# CY8C5888LTI_LP097 register map
File version: 0.1
Registers are 8-bit, read-write, no defined reset value unless marked. A register's access mark holds for its fields unless they carry their own. Offsets are from the block's base; [hi:lo] are bit positions; {n}, {i} and the like mark numbered series; 'fields as' and 'values as' point back to an identical list.

## Timer_RPM
Base 0x00000000
0x4000640C Timer_RPM_COUNTER 16-bit — UDB.A0 - Current Down Counter Value
0x4000642C Timer_RPM_PERIOD 16-bit — UDB.D0 - Assigned Period
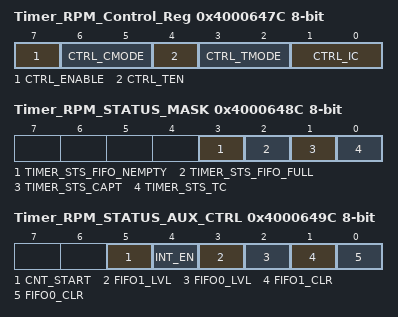
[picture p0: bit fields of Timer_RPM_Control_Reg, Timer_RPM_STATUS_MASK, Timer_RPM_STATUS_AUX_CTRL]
0x4000647C Timer_RPM_Control_Reg — UDB Control Register - Assigned Control Register Value
  [7] CTRL_ENABLE — Enable the Timer
  [6:5] CTRL_CMODE — Capture Mode
  [4] CTRL_TEN — Trigger Enable Bit
  [3:2] CTRL_TMODE — Trigger Mode
  [1:0] CTRL_IC — Interrupt Count
0x4000648C Timer_RPM_STATUS_MASK — UDB Status bits Interrupt Mask Enable Register
  [3] TIMER_STS_FIFO_NEMPTY ro — FIFO Empty status
  [2] TIMER_STS_FIFO_FULL ro — FIFO Full Status
  [1] TIMER_STS_CAPT ro — Enables the Interrupt on Capture
  [0] TIMER_STS_TC ro — Enables the Interrupt on TC
0x4000649C Timer_RPM_STATUS_AUX_CTRL — UDB Auxilliary Control Register
  [5] CNT_START — FIFO0 clear
    0=E_CNT_START0 (Disable counter); 1=E_CNT_START1 (Enable counter)
  [4] INT_EN
    0=E_INT_EN0 (Interrupt disabled); 1=E_INT_EN1 (Interrupt enabled)
  [3] FIFO1_LVL — FIFO level
    0=E_FIFO_LVL_0 (FIFO LVL: input mode: FIFO not full; output mode: FIFO not empty); 1=E_FIFO_LVL_1 (FIFO LVL: input mode: FIFO at least 1/2 empty; output mode: FIFO at least 1/2 full)
  [2] FIFO0_LVL — FIFO level
    values as FIFO1_LVL
  [1] FIFO1_CLR — FIFO1 clear
    0=E_FIFO_CLR_0 (Normal FIFO operation); 1=E_FIFO_CLR_1 (Clear FIFO state)
  [0] FIFO0_CLR — FIFO0 clear
    values as FIFO1_CLR

## PWM_motor
Base 0x00000000
0x4000642A PWM_motor_COMPARE_Reg_ — UDB.D0 - Assigned Compare Value
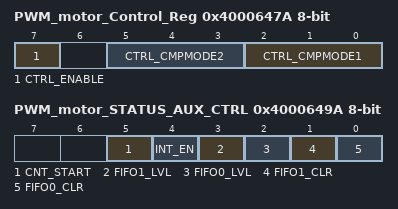
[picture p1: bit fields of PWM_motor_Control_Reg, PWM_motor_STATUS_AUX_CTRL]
0x4000647A PWM_motor_Control_Reg — UDB Control Register - Assigned Control Register Value
  [7] CTRL_ENABLE — Enable the PWM
  [5:3] CTRL_CMPMODE2 — Compare mode 2
  [2:0] CTRL_CMPMODE1 — Compare mode 1
0x4000649A PWM_motor_STATUS_AUX_CTRL — UDB Auxilliary Control Register
  [5] CNT_START — FIFO0 clear
    0=E_CNT_START0 (Disable counter); 1=E_CNT_START1 (Enable counter)
  [4] INT_EN
    0=E_INT_EN0 (Interrupt disabled); 1=E_INT_EN1 (Interrupt enabled)
  [3] FIFO1_LVL — FIFO level
    0=E_FIFO_LVL_0 (FIFO LVL: input mode: FIFO not full; output mode: FIFO not empty); 1=E_FIFO_LVL_1 (FIFO LVL: input mode: FIFO at least 1/2 empty; output mode: FIFO at least 1/2 full)
  [2] FIFO0_LVL — FIFO level
    values as FIFO1_LVL
  [1] FIFO1_CLR — FIFO1 clear
    0=E_FIFO_CLR_0 (Normal FIFO operation); 1=E_FIFO_CLR_1 (Clear FIFO state)
  [0] FIFO0_CLR — FIFO0 clear
    values as FIFO1_CLR

## Control_Reg_motor_reset
Base 0x4000647B
0x00 Control_Reg_motor_reset_CONTROL_REG

## CAN_1
Base 0x00000000
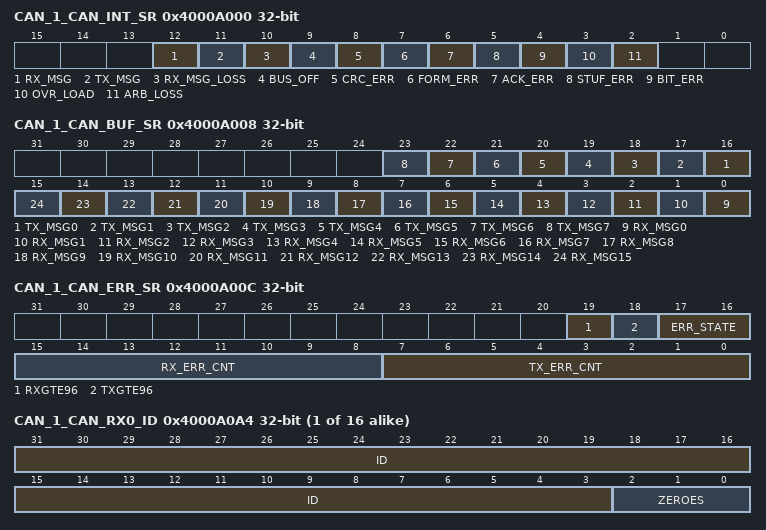
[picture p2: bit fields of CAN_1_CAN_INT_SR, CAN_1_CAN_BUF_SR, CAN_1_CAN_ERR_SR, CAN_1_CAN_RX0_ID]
0x4000A000 CAN_1_CAN_INT_SR 32-bit — The interrupt status register stores internal interrupt events. ? Once a bit is set it remains set until it is cleared by writing a '1' to it. ? The interrupt enable register has no effect on the interrupt status register. ? A pending interrupt occurs when the flag is set to '1'. To acknowledge an interrupt, set the flag to '1'
  [12] RX_MSG — Msg Recieved
  [11] TX_MSG — Tx msg Sent
  [10] RX_MSG_LOSS — Rx msg loss Interrupt
  [9] BUS_OFF — Bus Off State
  [8] CRC_ERR — CRC Error Interrupt
  [7] FORM_ERR — Form Error Interrupt
  [6] ACK_ERR — Ack Error Interrupt
  [5] STUF_ERR — Stuff Error Interrupt
  [4] BIT_ERR — Bit Error Interrupt
  [3] OVR_LOAD — Overload Interrupt
  [2] ARB_LOSS — Arbitration Loss
0x4000A008 CAN_1_CAN_BUF_SR 32-bit — These status indicators bundle the respective flags from all RxMessage and TxMessage buffers. ? Note All flags are read only. To acknowledge a MsgAv flag, the CPU must write to the respective RxMessage buffer
  [n+16] TX_MSG{n} (n=0..7) — Tx req Pending for Tx Msg{n}
  [n] RX_MSG{n} (n=0..15) — Rx Msg{n} Available
0x4000A00C CAN_1_CAN_ERR_SR 32-bit — Status indicators are provided to report the CAN controller error state, receive error count, and transmit error count. ? Special flags report error counter values equal to or in excess of 96 errors are available to indicate heavily disturbed bus situations. ? The transmitter error counter according to the CAN standard. When it is greater than 255 Decimal, it is fixed at 255 Decimal.
  [19] RXGTE96 — Rx Error Count is greater or equal to 96 Decimal
  [18] TXGTE96 — Tx Error Count is greater or equal to 96 Decimal
  [17:16] ERR_STATE — Error State of CAN node, 00 error active, 01 error passive, 1x bus off
  [15:8] RX_ERR_CNT — Rx error Count. When in bus-off state,this counter is used to count 128 groups of 11 recessive bits
  [7:0] TX_ERR_CNT — Tx error Count
{0x4000A024+0x10*i} CAN_1_CAN_TX{i}_ID 32-bit (i=0..7) — CAN Tx Msg Identifier
  [31:3] ID — Tx Msg Indentifier
{0x4000A028+0x10*i} CAN_1_CAN_TX{i}_DH 32-bit (i=0..7) — CAN Tx Msg Upper Data Bytes
  [31:0] DATA_HIGH — Upper Data Bytes
{0x4000A02C+0x10*i} CAN_1_CAN_TX{i}_DL 32-bit (i=0..7) — CAN Tx Msg Lower Data Bytes
  [31:0] DATA_LOW — Lower Data Bytes
{0x4000A0A4+0x20*i} CAN_1_CAN_RX{i}_ID 32-bit (i=0..15) — The register contains Rx Msg Identifier
  [31:3] ID — Rx Msg Indentifier
  [2:0] ZEROES — zeros
{0x4000A0A8+0x20*i} CAN_1_CAN_RX{i}_DH 32-bit (i=0..15) — The register contains the Rx Msg Upper Data Bytes
  [31:0] DATA_HIGH — Upper Data Bytes
{0x4000A0AC+0x20*i} CAN_1_CAN_RX{i}_DL 32-bit (i=0..15) — The register contains the Rx Msg Lover Data Bytes
  [31:0] DATA_LOW — Lower Data Bytes

## VDAC8_1
Base 0x00000000
0x400043A8 VDAC8_PM_ACT_CFG — Active Power Mode Configuration Register 8
  [4:0] en_dac — Enable DAC block(s). Populated subsystems are counted from the LSB
0x400043B8 VDAC8_PM_STBY_CFG — Standby Power Mode Configuration Register 8
  fields as VDAC8_PM_ACT_CFG
0x4000460A VDAC8_TR
  [7:0] tr — 8 Calibration bits
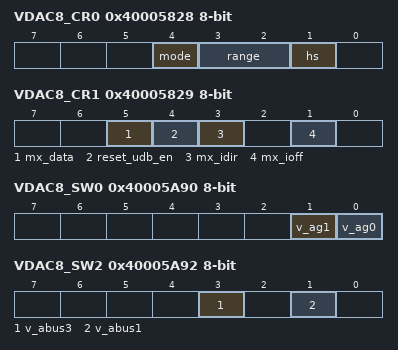
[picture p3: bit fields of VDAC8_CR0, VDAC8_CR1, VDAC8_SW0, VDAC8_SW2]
0x40005828 VDAC8_CR0 — DAC Block Control Register 0
  [4] mode ro — Mode Bit
    0=DAC_MODE_V (voltage DAC); 1=DAC_MODE_I (current DAC)
  [3:2] range — Ranges for mode=0 (VDAC) and mode=1 (IDAC)
    0=DAC_RANGE_0 (x0=0V to 4*vref (1.024V); 0 to 31.875uA); 1=DAC_RANGE_1 (x1=0V to 16*vref (4.096V); 0 to 255uA); 2=DAC_RANGE_2 (x0=0V to 4*vref (1.024V); 0 to 2.040mA); 3=DAC_RANGE_3 (x1=0V to 16*vref (4.096V); not used)
  [1] hs — High Speed Bit
    0=DAC_HS_LOWPOWER (regular (low power)); 1=DAC_HS_HIGHSPEED (high speed (higher power))
0x40005829 VDAC8_CR1 — DAC Block Control Register 1
  [5] mx_data — Select DATA source
    0=MX_DATA_REG (Select register source (DACxn_D)); 1=MX_DATA_UDB (Select UDB source)
  [4] reset_udb_en — DAC reset enable
    0=RESET_UDB_EN_DISABLE (Disable DAC Reset Source from UDB (System reset always resets)); 1=RESET_UDB_EN_ENABLE (Enable DAC Reset Source from UDB)
  [3] mx_idir — Mux selection for DAC current direction control
    0=MX_IDIR_REG (Register source idirbit selected); 1=MX_IDIR_UDB (UDB ictrl selected)
  [1] mx_ioff — Mux selection for DAC current off control
    0=MX_IOFF_REG (Register source ioffbit selected); 1=MX_IOFF_UDB (UDB ictrl selected)
0x40005A90 VDAC8_SW0 — DAC Analog Routing Register 0
  [1] v_ag1 — Connect voltage output to analog global of same side
    0=AG_NC (not connected); 1=AG_CONNECTED (Connect to Analog Global)
  [0] v_ag0 — Connect voltage output to analog global of same side
    values as v_ag1
0x40005A92 VDAC8_SW2 — DAC Analog Routing Register 2
  [3] v_abus3 — Connect voltage output to analog (local) bus of the same side
    0=ABUS_NC (not connected); 1=ABUS_CONNECTED (Connect to Analog (local) Bus)
  [1] v_abus1 — Connect voltage output to analog (local) bus of the same side
    values as v_abus3
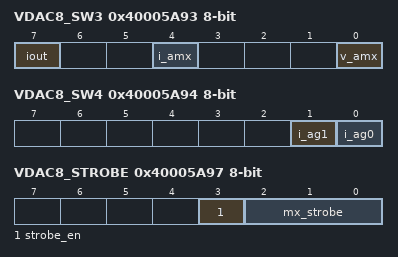
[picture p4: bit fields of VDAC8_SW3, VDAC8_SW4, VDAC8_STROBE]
0x40005A93 VDAC8_SW3 — DAC Analog Routing Register 3
  [7] iout — Connect current output to pad
    0=IOUT_NC (not connected); 1=IOUT_CONNECT (Connect to pad)
  [4] i_amx — Connect current output to Analog Mux Bus
    0=AMX_NC (not connected); 1=AMX_CONNECTED (Connect to AMUXBUS)
  [0] v_amx — Connect voltage output to Analog Mux Bus
    values as i_amx
0x40005A94 VDAC8_SW4 — DAC Analog Routing Register 4
  [1] i_ag1 — Connect current output to analog global of same side
    values as VDAC8_SW0.v_ag1
  [0] i_ag0 — Connect current output to analog global of same side
    values as VDAC8_SW0.v_ag1
0x40005A97 VDAC8_STROBE — DAC Strobe Register
  [3] strobe_en — Strobe gating control (See mx_strobe==3'h0)
    0=disable strobe; 1=enable strobe
  [2:0] mx_strobe — Strobe source selection
    0=MX_STROBE_BUSWRITE (Select bus write strobe source (Enable gater regardless of strobe_en setting)); 1=MX_STROBE_UDB_SRC (Select UDB strobe source); 2=MX_STROBE_NC_2 (NC); 3=MX_STROBE_NC_3 (NC); {v}=MX_STROBE_CLK_A{v-4}_DIG (Select clk_a{v-4}_dig) (v=4..7)
0x40005B82 VDAC8_DATA — DAC Data Register
  [7:0] data — 8 DAC Data bits
